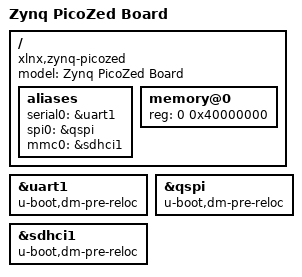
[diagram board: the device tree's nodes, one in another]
// SPDX-License-Identifier: GPL-2.0+
/*
 * Avnet PicoZed board DTS
 *
 * Copyright (C) 2015 Xilinx, Inc.
 */
/dts-v1/;
#include "zynq-7000.dtsi"

/ {
	model = "Zynq PicoZed Board";
	compatible = "xlnx,zynq-picozed", "xlnx,zynq-7000";

	aliases {
		serial0 = &uart1;
		spi0 = &qspi;
		mmc0 = &sdhci1;
	};

	memory@0 {
		device_type = "memory";
		reg = <0 0x40000000>;
	};
};

&uart1 {
	u-boot,dm-pre-reloc;
	status = "okay";
};

&qspi {
	u-boot,dm-pre-reloc;
	status = "okay";
};

&sdhci1 {
	u-boot,dm-pre-reloc;
	status = "okay";
};
